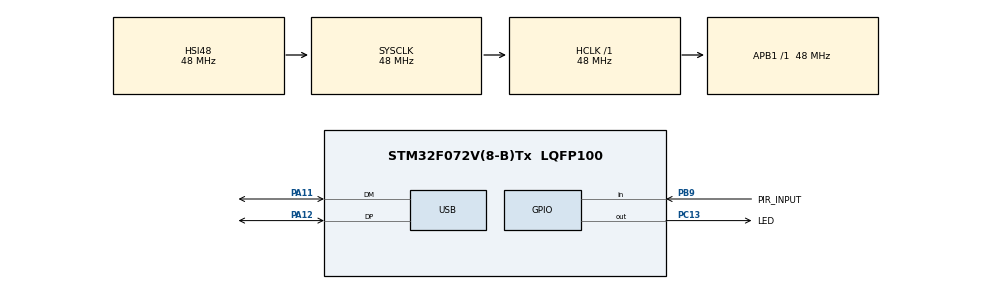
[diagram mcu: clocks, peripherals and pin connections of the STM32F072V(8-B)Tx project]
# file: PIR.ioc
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Mcu.Family=STM32F0
Mcu.Name=STM32F072V(8-B)Tx
Mcu.Package=LQFP100
NVIC.USB_IRQn=true\:0\:0\:false\:false\:true\:false\:true\:true
PA11.Mode=Device
PA11.Signal=USB_DM
PA12.Mode=Device
PA12.Signal=USB_DP
PB9.GPIO_Label=PIR_INPUT
PB9.Signal=GPIO_Input
PC13.GPIO_Label=LED
PC13.Signal=GPIO_Output
ProjectManager.HeapSize=0x200
ProjectManager.StackSize=0x400
ProjectManager.TargetToolchain=STM32CubeIDE
RCC.AHBFreq_Value=48000000
RCC.APB1Freq_Value=48000000
RCC.APB1TimFreq_Value=48000000
RCC.HCLKFreq_Value=48000000
RCC.SYSCLKFreq_VALUE=48000000
RCC.SYSCLKSource=RCC_SYSCLKSOURCE_HSI48
USB_DEVICE.CLASS_NAME_FS=CDC
USB_DEVICE.VirtualMode=Cdc
USB_DEVICE.VirtualModeFS=Cdc_FS
VP_USB_DEVICE_VS_USB_DEVICE_CDC_FS.Mode=CDC_FS
board=custom

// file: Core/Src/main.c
/* USER CODE BEGIN Header */
/**
  ******************************************************************************
  * @file           : main.c
  * @brief          : Main program body
  ******************************************************************************
  * @attention
  *
  * Copyright (c) 2023 STMicroelectronics.
  * All rights reserved.
  *
  * This software is licensed under terms that can be found in the LICENSE file
  * in the root directory of this software component.
  * If no LICENSE file comes with this software, it is provided AS-IS.
  *
  ******************************************************************************
  */
/* USER CODE END Header */
#include "main.h"
#include "usb_device.h"

void SystemClock_Config(void);
static void MX_GPIO_Init(void);

int main(void)
{

  /* MCU Configuration--------------------------------------------------------*/

  /* Reset of all peripherals, Initializes the Flash interface and the Systick. */
  HAL_Init();

  /* Configure the system clock */
  SystemClock_Config();

  /* Initialize all configured peripherals */
  MX_GPIO_Init();
  MX_USB_DEVICE_Init();
  /* USER CODE BEGIN 2 */
//  if (HAL_GPIO_ReadPin(PIR_INPUT_GPIO_Port, PIR_INPUT_Pin) == GPIO_PIN_SET)
//  {
//	  HAL_GPIO_WritePin(LED_GPIO_Port, LED_Pin, GPIO_PIN_SET);
//  }
  /* USER CODE END 2 */

  /* Infinite loop */
  /* USER CODE BEGIN WHILE */
  uint8_t data[8] = {0};
  while (1)
  {   int pir = HAL_GPIO_ReadPin(PIR_INPUT_GPIO_Port, PIR_INPUT_Pin);
      sprintf(data, "%d\r",pir);
	  CDC_Transmit_FS(data, strlen(data));

    /* USER CODE END WHILE */

  }
}

void SystemClock_Config(void)
{
  RCC_OscInitTypeDef RCC_OscInitStruct = {0};
  RCC_ClkInitTypeDef RCC_ClkInitStruct = {0};
  RCC_PeriphCLKInitTypeDef PeriphClkInit = {0};

  /** Initializes the RCC Oscillators according to the specified parameters
  * in the RCC_OscInitTypeDef structure.
  */
  RCC_OscInitStruct.OscillatorType = RCC_OSCILLATORTYPE_HSI48;
  RCC_OscInitStruct.HSI48State = RCC_HSI48_ON;
  RCC_OscInitStruct.PLL.PLLState = RCC_PLL_NONE;
  if (HAL_RCC_OscConfig(&RCC_OscInitStruct) != HAL_OK)
  {
    Error_Handler();
  }

  /** Initializes the CPU, AHB and APB buses clocks
  */
  RCC_ClkInitStruct.ClockType = RCC_CLOCKTYPE_HCLK|RCC_CLOCKTYPE_SYSCLK
                              |RCC_CLOCKTYPE_PCLK1;
  RCC_ClkInitStruct.SYSCLKSource = RCC_SYSCLKSOURCE_HSI48;
  RCC_ClkInitStruct.AHBCLKDivider = RCC_SYSCLK_DIV1;
  RCC_ClkInitStruct.APB1CLKDivider = RCC_HCLK_DIV1;

  if (HAL_RCC_ClockConfig(&RCC_ClkInitStruct, FLASH_LATENCY_1) != HAL_OK)
  {
    Error_Handler();
  }
  PeriphClkInit.PeriphClockSelection = RCC_PERIPHCLK_USB;
  PeriphClkInit.UsbClockSelection = RCC_USBCLKSOURCE_HSI48;

  if (HAL_RCCEx_PeriphCLKConfig(&PeriphClkInit) != HAL_OK)
  {
    Error_Handler();
  }
}

static void MX_GPIO_Init(void)
{
  GPIO_InitTypeDef GPIO_InitStruct = {0};

  /* GPIO Ports Clock Enable */
  __HAL_RCC_GPIOC_CLK_ENABLE();
  __HAL_RCC_GPIOA_CLK_ENABLE();
  __HAL_RCC_GPIOB_CLK_ENABLE();

  /*Configure GPIO pin Output Level */
  HAL_GPIO_WritePin(LED_GPIO_Port, LED_Pin, GPIO_PIN_RESET);

  /*Configure GPIO pin : LED_Pin */
  GPIO_InitStruct.Pin = LED_Pin;
  GPIO_InitStruct.Mode = GPIO_MODE_OUTPUT_PP;
  GPIO_InitStruct.Pull = GPIO_NOPULL;
  GPIO_InitStruct.Speed = GPIO_SPEED_FREQ_LOW;
  HAL_GPIO_Init(LED_GPIO_Port, &GPIO_InitStruct);

  /*Configure GPIO pin : PIR_INPUT_Pin */
  GPIO_InitStruct.Pin = PIR_INPUT_Pin;
  GPIO_InitStruct.Mode = GPIO_MODE_INPUT;
  GPIO_InitStruct.Pull = GPIO_NOPULL;
  HAL_GPIO_Init(PIR_INPUT_GPIO_Port, &GPIO_InitStruct);

}

void Error_Handler(void)
{
  __disable_irq();
  while (1)
  {
  }
}
